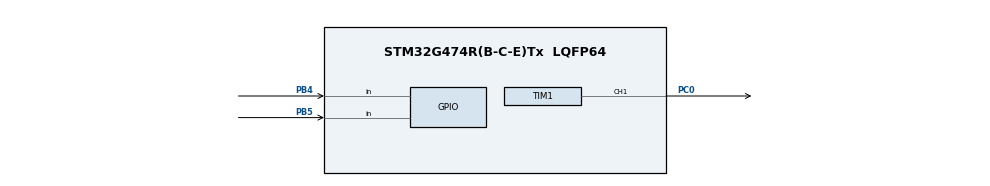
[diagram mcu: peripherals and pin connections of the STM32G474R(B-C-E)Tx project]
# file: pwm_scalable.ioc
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Mcu.Family=STM32G4
Mcu.Name=STM32G474R(B-C-E)Tx
Mcu.Package=LQFP64
NVIC.PriorityGroup=NVIC_PRIORITYGROUP_4
PB4.Signal=GPIO_Input
PB5.Signal=GPIO_Input
PC0.Signal=S_TIM1_CH1
ProjectManager.HeapSize=0x200
ProjectManager.StackSize=0x400
ProjectManager.TargetToolchain=STM32CubeIDE
RCC.ADC12Freq_Value=170000000
RCC.ADC345Freq_Value=170000000
RCC.AHBFreq_Value=170000000
RCC.APB1Freq_Value=170000000
RCC.APB1TimFreq_Value=170000000
RCC.APB2Freq_Value=170000000
RCC.APB2TimFreq_Value=170000000
RCC.CortexFreq_Value=170000000
RCC.EXTERNAL_CLOCK_VALUE=12288000
RCC.HCLKFreq_Value=170000000
RCC.HSE_VALUE=24000000
RCC.HSI48_VALUE=48000000
RCC.HSI_VALUE=16000000
RCC.LSE_VALUE=32768
RCC.PLLM=RCC_PLLM_DIV4
RCC.PLLN=85
RCC.RTCClockSelection=RCC_RTCCLKSOURCE_LSE
RCC.SYSCLKFreq_VALUE=170000000
RCC.SYSCLKSource=RCC_SYSCLKSOURCE_PLLCLK
RCC.USBFreq_Value=170000000
RCC.VCOOutputFreq_Value=340000000
SH.S_TIM1_CH1.0=TIM1_CH1,PWM Generation1 CH1
TIM1.Channel-PWM\ Generation1\ CH1=TIM_CHANNEL_1
TIM1.PeriodNoDither=250
VP_SYS_VS_DBSignals.Mode=DisableDeadBatterySignals
board=NUCLEO-G474RE

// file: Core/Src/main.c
/* USER CODE BEGIN Header */
/**
  ******************************************************************************
  * @file           : main.c
  * @brief          : Main program body
  ******************************************************************************
  * @attention
  *
  * Copyright (c) 2026 STMicroelectronics.
  * All rights reserved.
  *
  * This software is licensed under terms that can be found in the LICENSE file
  * in the root directory of this software component.
  * If no LICENSE file comes with this software, it is provided AS-IS.
  *
  ******************************************************************************
  */
/*
 * Σε αυτό το παράδειγμα,
 * εφμανίζουμε στην PWM έξοδο PC0 του χρονιστή TIM1,
 * δεδομένο duty cycle κάθε φορά σύμφωνα με τον δείκτη ptr.
 * Αυξάνουμε DC κατά 1 όταν πατάω το B3
 * Μειώνουμε DC κατά 1 όταν πατάω το Β4
 * Ιδιαίτερη έμφαση στο debounce
 * */
/* USER CODE END Header */
#include "main.h"

/* USER CODE BEGIN PV */
/* Καθολικός πίνακας τιμών CCR1 και δείκτης (ορατά στο Live Expressions) */
const uint16_t OCR1A_table[15] = {0, 5, 30, 46, 66, 87, 107, 128, 148, 168, 189, 209, 230, 250, 255};
volatile uint8_t ptr = 7; // Θέση 7 -> τιμή 128 (50% Duty Cycle)
/* USER CODE END PV */

void SystemClock_Config(void);
static void MX_GPIO_Init(void);
static void MX_TIM1_Init(void);

int main(void)
{

  /* MCU Configuration--------------------------------------------------------*/

  /* Reset of all peripherals, Initializes the Flash interface and the Systick. */
  LL_APB2_GRP1_EnableClock(LL_APB2_GRP1_PERIPH_SYSCFG);
  LL_APB1_GRP1_EnableClock(LL_APB1_GRP1_PERIPH_PWR);

  /* System interrupt init*/
  NVIC_SetPriorityGrouping(NVIC_PRIORITYGROUP_4);

  /** Disable the internal Pull-Up in Dead Battery pins of UCPD peripheral
  */
  LL_PWR_DisableUCPDDeadBattery();

  /* Configure the system clock */
  SystemClock_Config();

  /* Initialize all configured peripherals */
  MX_GPIO_Init();
  MX_TIM1_Init();

  /* USER CODE BEGIN 2 */
  /* Ενεργοποίηση εξόδων και εκκίνηση του PWM */
  LL_TIM_EnableAllOutputs(TIM1);
  LL_TIM_CC_EnableChannel(TIM1, LL_TIM_CHANNEL_CH1);
  LL_TIM_OC_SetCompareCH1(TIM1, OCR1A_table[ptr]);
  LL_TIM_EnableCounter(TIM1);
  /* USER CODE END 2 */

  /* Infinite loop */
  while (1)
  {

    /* USER CODE BEGIN 3 */
    /* --- Έλεγχος PB4 (Αύξηση) - Active HIGH --- */
    if (LL_GPIO_IsInputPinSet(GPIOB, LL_GPIO_PIN_4)) {
        LL_mDelay(30); // Debounce κατά το πάτημα
        if (LL_GPIO_IsInputPinSet(GPIOB, LL_GPIO_PIN_4)) {
            if (ptr < 13) {
                ptr++;
                LL_TIM_OC_SetCompareCH1(TIM1, OCR1A_table[ptr]);
            }
            /* Αναμονή μέχρι να αφεθεί το κουμπί */
            while (LL_GPIO_IsInputPinSet(GPIOB, LL_GPIO_PIN_4)) {
                LL_mDelay(10);
            }
            LL_mDelay(50); // Debounce κατά την απελευθέρωση
        }
    }

    /* --- Έλεγχος PB5 (Μείωση) - Active HIGH --- */
    if (LL_GPIO_IsInputPinSet(GPIOB, LL_GPIO_PIN_5)) {
        LL_mDelay(30); // Debounce κατά το πάτημα
        if (LL_GPIO_IsInputPinSet(GPIOB, LL_GPIO_PIN_5)) {
            if (ptr > 1) {
                ptr--;
                LL_TIM_OC_SetCompareCH1(TIM1, OCR1A_table[ptr]);
            }
            /* Αναμονή μέχρι να αφεθεί το κουμπί */
            while (LL_GPIO_IsInputPinSet(GPIOB, LL_GPIO_PIN_5)) {
                LL_mDelay(10);
            }
            LL_mDelay(50); // Debounce κατά την απελευθέρωση
        }
    }
    /* USER CODE END 3 */
  }
}

void SystemClock_Config(void)
{
  LL_FLASH_SetLatency(LL_FLASH_LATENCY_4);
  while(LL_FLASH_GetLatency() != LL_FLASH_LATENCY_4)
  {
  }
  LL_PWR_EnableRange1BoostMode();
  LL_RCC_HSI_Enable();
   /* Wait till HSI is ready */
  while(LL_RCC_HSI_IsReady() != 1)
  {
  }

  LL_RCC_HSI_SetCalibTrimming(64);
  LL_RCC_PLL_ConfigDomain_SYS(LL_RCC_PLLSOURCE_HSI, LL_RCC_PLLM_DIV_4, 85, LL_RCC_PLLR_DIV_2);
  LL_RCC_PLL_EnableDomain_SYS();
  LL_RCC_PLL_Enable();
   /* Wait till PLL is ready */
  while(LL_RCC_PLL_IsReady() != 1)
  {
  }

  LL_RCC_SetSysClkSource(LL_RCC_SYS_CLKSOURCE_PLL);
  LL_RCC_SetAHBPrescaler(LL_RCC_SYSCLK_DIV_2);
   /* Wait till System clock is ready */
  while(LL_RCC_GetSysClkSource() != LL_RCC_SYS_CLKSOURCE_STATUS_PLL)
  {
  }

  /* Insure 1us transition state at intermediate medium speed clock*/
  for (__IO uint32_t i = (170 >> 1); i !=0; i--);

  /* Set AHB prescaler*/
  LL_RCC_SetAHBPrescaler(LL_RCC_SYSCLK_DIV_1);
  LL_RCC_SetAPB1Prescaler(LL_RCC_APB1_DIV_1);
  LL_RCC_SetAPB2Prescaler(LL_RCC_APB2_DIV_1);

  LL_Init1msTick(170000000);

  LL_SetSystemCoreClock(170000000);
}

static void MX_TIM1_Init(void)
{

  LL_TIM_InitTypeDef TIM_InitStruct = {0};
  LL_TIM_OC_InitTypeDef TIM_OC_InitStruct = {0};
  LL_TIM_BDTR_InitTypeDef TIM_BDTRInitStruct = {0};

  LL_GPIO_InitTypeDef GPIO_InitStruct = {0};

  /* Peripheral clock enable */
  LL_APB2_GRP1_EnableClock(LL_APB2_GRP1_PERIPH_TIM1);

  TIM_InitStruct.Prescaler = 0;
  TIM_InitStruct.CounterMode = LL_TIM_COUNTERMODE_UP;
  TIM_InitStruct.Autoreload = 255;
  TIM_InitStruct.ClockDivision = LL_TIM_CLOCKDIVISION_DIV1;
  TIM_InitStruct.RepetitionCounter = 0;
  LL_TIM_Init(TIM1, &TIM_InitStruct);
  LL_TIM_DisableARRPreload(TIM1);
  LL_TIM_OC_EnablePreload(TIM1, LL_TIM_CHANNEL_CH1);
  TIM_OC_InitStruct.OCMode = LL_TIM_OCMODE_PWM1;
  TIM_OC_InitStruct.OCState = LL_TIM_OCSTATE_DISABLE;
  TIM_OC_InitStruct.OCNState = LL_TIM_OCSTATE_DISABLE;
  TIM_OC_InitStruct.CompareValue = 128;
  TIM_OC_InitStruct.OCPolarity = LL_TIM_OCPOLARITY_HIGH;
  TIM_OC_InitStruct.OCNPolarity = LL_TIM_OCPOLARITY_HIGH;
  TIM_OC_InitStruct.OCIdleState = LL_TIM_OCIDLESTATE_LOW;
  TIM_OC_InitStruct.OCNIdleState = LL_TIM_OCIDLESTATE_LOW;
  LL_TIM_OC_Init(TIM1, LL_TIM_CHANNEL_CH1, &TIM_OC_InitStruct);
  LL_TIM_OC_DisableFast(TIM1, LL_TIM_CHANNEL_CH1);
  LL_TIM_SetTriggerOutput(TIM1, LL_TIM_TRGO_RESET);
  LL_TIM_SetTriggerOutput2(TIM1, LL_TIM_TRGO2_RESET);
  LL_TIM_DisableMasterSlaveMode(TIM1);
  TIM_BDTRInitStruct.OSSRState = LL_TIM_OSSR_DISABLE;
  TIM_BDTRInitStruct.OSSIState = LL_TIM_OSSI_DISABLE;
  TIM_BDTRInitStruct.LockLevel = LL_TIM_LOCKLEVEL_OFF;
  TIM_BDTRInitStruct.DeadTime = 0;
  TIM_BDTRInitStruct.BreakState = LL_TIM_BREAK_DISABLE;
  TIM_BDTRInitStruct.BreakPolarity = LL_TIM_BREAK_POLARITY_HIGH;
  TIM_BDTRInitStruct.BreakFilter = LL_TIM_BREAK_FILTER_FDIV1;
  TIM_BDTRInitStruct.BreakAFMode = LL_TIM_BREAK_AFMODE_INPUT;
  TIM_BDTRInitStruct.Break2State = LL_TIM_BREAK2_DISABLE;
  TIM_BDTRInitStruct.Break2Polarity = LL_TIM_BREAK2_POLARITY_HIGH;
  TIM_BDTRInitStruct.Break2Filter = LL_TIM_BREAK2_FILTER_FDIV1;
  TIM_BDTRInitStruct.Break2AFMode = LL_TIM_BREAK_AFMODE_INPUT;
  TIM_BDTRInitStruct.AutomaticOutput = LL_TIM_AUTOMATICOUTPUT_DISABLE;
  LL_TIM_BDTR_Init(TIM1, &TIM_BDTRInitStruct);
  LL_AHB2_GRP1_EnableClock(LL_AHB2_GRP1_PERIPH_GPIOC);
  /**TIM1 GPIO Configuration
  PC0   ------> TIM1_CH1
  */
  GPIO_InitStruct.Pin = LL_GPIO_PIN_0;
  GPIO_InitStruct.Mode = LL_GPIO_MODE_ALTERNATE;
  GPIO_InitStruct.Speed = LL_GPIO_SPEED_FREQ_LOW;
  GPIO_InitStruct.OutputType = LL_GPIO_OUTPUT_PUSHPULL;
  GPIO_InitStruct.Pull = LL_GPIO_PULL_NO;
  GPIO_InitStruct.Alternate = LL_GPIO_AF_2;
  LL_GPIO_Init(GPIOC, &GPIO_InitStruct);

}

static void MX_GPIO_Init(void)
{
  LL_GPIO_InitTypeDef GPIO_InitStruct = {0};

  /* GPIO Ports Clock Enable */
  LL_AHB2_GRP1_EnableClock(LL_AHB2_GRP1_PERIPH_GPIOC);
  LL_AHB2_GRP1_EnableClock(LL_AHB2_GRP1_PERIPH_GPIOB);

  /* PB4 και PB5 με Pull-Down για Active HIGH */
  GPIO_InitStruct.Pin = LL_GPIO_PIN_4;
  GPIO_InitStruct.Mode = LL_GPIO_MODE_INPUT;
  GPIO_InitStruct.Pull = LL_GPIO_PULL_DOWN;
  LL_GPIO_Init(GPIOB, &GPIO_InitStruct);

  GPIO_InitStruct.Pin = LL_GPIO_PIN_5;
  GPIO_InitStruct.Mode = LL_GPIO_MODE_INPUT;
  GPIO_InitStruct.Pull = LL_GPIO_PULL_DOWN;
  LL_GPIO_Init(GPIOB, &GPIO_InitStruct);

}

void Error_Handler(void)
{
  __disable_irq();
  while (1)
  {
  }
}
